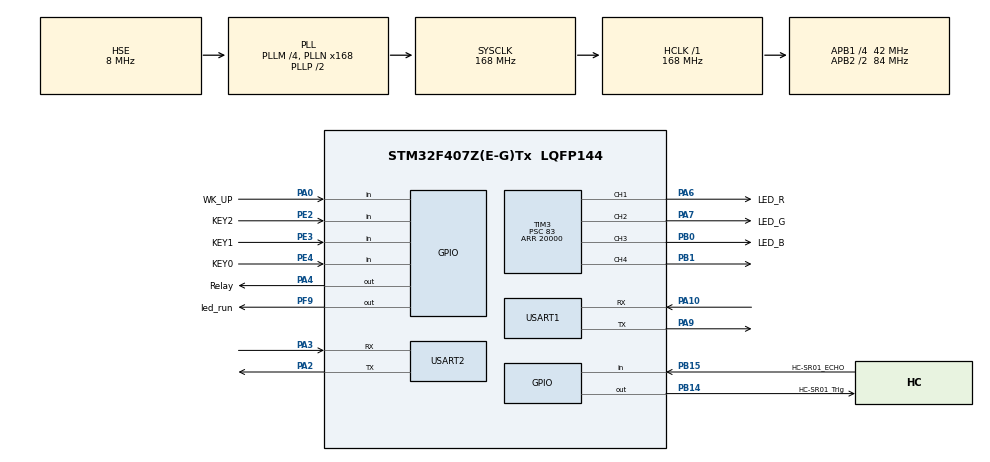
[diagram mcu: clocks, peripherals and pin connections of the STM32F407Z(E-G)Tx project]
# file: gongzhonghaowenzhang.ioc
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Mcu.Family=STM32F4
Mcu.Name=STM32F407Z(E-G)Tx
Mcu.Package=LQFP144
NVIC.PriorityGroup=NVIC_PRIORITYGROUP_4
NVIC.RCC_IRQn=true\:0\:0\:false\:false\:true\:true
NVIC.TIM2_IRQn=true\:0\:0\:false\:false\:true\:true
NVIC.TIM3_IRQn=true\:0\:0\:false\:false\:true\:true
NVIC.TIM7_IRQn=true\:0\:0\:false\:false\:true\:true
NVIC.USART1_IRQn=true\:0\:0\:false\:false\:true\:true
NVIC.USART2_IRQn=true\:0\:0\:false\:false\:true\:true
PA0-WKUP.GPIO_Label=WK_UP
PA0-WKUP.GPIO_PuPd=GPIO_PULLDOWN
PA0-WKUP.Signal=GPIO_Input
PA10.Mode=Asynchronous
PA10.Signal=USART1_RX
PA13.Mode=JTAG_5_pins
PA13.Signal=SYS_JTMS-SWDIO
PA14.Mode=JTAG_5_pins
PA14.Signal=SYS_JTCK-SWCLK
PA15.Mode=JTAG_5_pins
PA15.Signal=SYS_JTDI
PA2.Mode=Asynchronous
PA2.Signal=USART2_TX
PA3.Mode=Asynchronous
PA3.Signal=USART2_RX
PA4.GPIO_Label=Relay
PA4.Signal=GPIO_Output
PA6.GPIO_Label=LED_R
PA6.Signal=S_TIM3_CH1
PA7.GPIO_Label=LED_G
PA7.Signal=S_TIM3_CH2
PA9.Mode=Asynchronous
PA9.Signal=USART1_TX
PB0.GPIO_Label=LED_B
PB0.Signal=S_TIM3_CH3
PB1.Signal=S_TIM3_CH4
PB14.GPIO_Label=HC-SR01_Trig
PB14.GPIO_PuPd=GPIO_PULLDOWN
PB14.GPIO_Speed=GPIO_SPEED_FREQ_HIGH
PB14.PinState=GPIO_PIN_RESET
PB14.Signal=GPIO_Output
PB15.GPIO_Label=HC-SR01_ECHO
PB15.Signal=GPIO_Input
PB3.Mode=JTAG_5_pins
PB3.Signal=SYS_JTDO-SWO
PB4.Mode=JTAG_5_pins
PB4.Signal=SYS_JTRST
PE2.GPIO_Label=KEY2
PE2.GPIO_PuPd=GPIO_PULLUP
PE2.Signal=GPIO_Input
PE3.GPIO_Label=KEY1
PE3.GPIO_PuPd=GPIO_PULLUP
PE3.Signal=GPIO_Input
PE4.GPIO_Label=KEY0
PE4.GPIO_PuPd=GPIO_PULLUP
PE4.Signal=GPIO_Input
PF9.GPIO_Label=led_run
PF9.Signal=GPIO_Output
PH0-OSC_IN.Mode=HSE-External-Oscillator
PH0-OSC_IN.Signal=RCC_OSC_IN
PH1-OSC_OUT.Mode=HSE-External-Oscillator
PH1-OSC_OUT.Signal=RCC_OSC_OUT
ProjectManager.HeapSize=0x200
ProjectManager.StackSize=0x400
ProjectManager.TargetToolchain=MDK-ARM V5
RCC.48MHZClocksFreq_Value=84000000
RCC.AHBFreq_Value=168000000
RCC.APB1CLKDivider=RCC_HCLK_DIV4
RCC.APB1Freq_Value=42000000
RCC.APB1TimFreq_Value=84000000
RCC.APB2CLKDivider=RCC_HCLK_DIV2
RCC.APB2Freq_Value=84000000
RCC.APB2TimFreq_Value=168000000
RCC.CortexFreq_Value=168000000
RCC.HCLKFreq_Value=168000000
RCC.HSE_VALUE=8000000
RCC.HSI_VALUE=16000000
RCC.LSE_VALUE=32768
RCC.PLLM=4
RCC.PLLN=168
RCC.PLLSourceVirtual=RCC_PLLSOURCE_HSE
RCC.SYSCLKFreq_VALUE=168000000
RCC.SYSCLKSource=RCC_SYSCLKSOURCE_PLLCLK
RCC.VCOOutputFreq_Value=336000000
SH.S_TIM3_CH1.0=TIM3_CH1,PWM Generation1 CH1
SH.S_TIM3_CH2.0=TIM3_CH2,PWM Generation2 CH2
SH.S_TIM3_CH3.0=TIM3_CH3,PWM Generation3 CH3
SH.S_TIM3_CH4.0=TIM3_CH4,PWM Generation4 CH4
TIM2.CounterMode=TIM_COUNTERMODE_UP
TIM2.Period=65535
TIM2.Prescaler=84-1
TIM3.Channel-PWM\ Generation1\ CH1=TIM_CHANNEL_1
TIM3.Channel-PWM\ Generation2\ CH2=TIM_CHANNEL_2
TIM3.Channel-PWM\ Generation3\ CH3=TIM_CHANNEL_3
TIM3.Channel-PWM\ Generation4\ CH4=TIM_CHANNEL_4
TIM3.Period=20000
TIM3.Prescaler=83
TIM7.Period=10
TIM7.Prescaler=8399
USART1.VirtualMode=VM_ASYNC
USART2.VirtualMode=VM_ASYNC
VP_TIM2_VS_ClockSourceINT.Mode=Internal
VP_TIM3_VS_ClockSourceINT.Mode=Internal
VP_TIM7_VS_ClockSourceINT.Mode=Enable_Timer
board=custom

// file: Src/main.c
/* USER CODE BEGIN Header */
/**
  ******************************************************************************
  * @file           : main.c
  * @brief          : Main program body
  ******************************************************************************
  ** This notice applies to any and all portions of this file
  * that are not between comment pairs USER CODE BEGIN and
  * USER CODE END. Other portions of this file, whether
  * inserted by the user or by software development tools
  * are owned by their respective copyright owners.
  *
  * COPYRIGHT(c) 2021 STMicroelectronics
  *
  * Redistribution and use in source and binary forms, with or without modification,
  * are permitted provided that the following conditions are met:
  *   1. Redistributions of source code must retain the above copyright notice,
  *      this list of conditions and the following disclaimer.
  *   2. Redistributions in binary form must reproduce the above copyright notice,
  *      this list of conditions and the following disclaimer in the documentation
  *      and/or other materials provided with the distribution.
  *   3. Neither the name of STMicroelectronics nor the names of its contributors
  *      may be used to endorse or promote products derived from this software
  *      without specific prior written permission.
  *
  * THIS SOFTWARE IS PROVIDED BY THE COPYRIGHT HOLDERS AND CONTRIBUTORS "AS IS"
  * AND ANY EXPRESS OR IMPLIED WARRANTIES, INCLUDING, BUT NOT LIMITED TO, THE
  * IMPLIED WARRANTIES OF MERCHANTABILITY AND FITNESS FOR A PARTICULAR PURPOSE ARE
  * DISCLAIMED. IN NO EVENT SHALL THE COPYRIGHT HOLDER OR CONTRIBUTORS BE LIABLE
  * FOR ANY DIRECT, INDIRECT, INCIDENTAL, SPECIAL, EXEMPLARY, OR CONSEQUENTIAL
  * DAMAGES (INCLUDING, BUT NOT LIMITED TO, PROCUREMENT OF SUBSTITUTE GOODS OR
  * SERVICES; LOSS OF USE, DATA, OR PROFITS; OR BUSINESS INTERRUPTION) HOWEVER
  * CAUSED AND ON ANY THEORY OF LIABILITY, WHETHER IN CONTRACT, STRICT LIABILITY,
  * OR TORT (INCLUDING NEGLIGENCE OR OTHERWISE) ARISING IN ANY WAY OUT OF THE USE
  * OF THIS SOFTWARE, EVEN IF ADVISED OF THE POSSIBILITY OF SUCH DAMAGE.
  *
  ******************************************************************************
  */
/* USER CODE END Header */

#include "main.h"
#include "tim.h"
#include "usart.h"
#include "gpio.h"

/* USER CODE BEGIN Includes */
#include "user_key.h"
#include "user_delay.h"
#include "hcsr04.h"
/* USER CODE END Includes */

void SystemClock_Config(void);

int main(void)
{
  /* USER CODE BEGIN 1 */
	uint8_t key = 0,t=0;
	float distant = 0;
  /* USER CODE END 1 */

  /* MCU Configuration--------------------------------------------------------*/

  /* Reset of all peripherals, Initializes the Flash interface and the Systick. */
  HAL_Init();

  /* Configure the system clock */
  SystemClock_Config();

  /* Initialize all configured peripherals */
  MX_GPIO_Init();
  MX_USART2_UART_Init();
  MX_TIM3_Init();
  MX_USART1_UART_Init();
  MX_TIM2_Init();
  MX_TIM7_Init();
  /* USER CODE BEGIN 2 */
  HAL_Delay_us_init(168);
  /* USER CODE END 2 */

  /* Infinite loop */
  while (1)
  {

    /* USER CODE BEGIN 3 */
//		distant =  HCSR04_Get_Time();
//		key=KEY_Scan(0);
//		switch (key)
//		{
//			case WKUP_PRES:			//
//				PWM_Output(1);
//				printf("rotate -90��\r\n");
//				break;
//			case KEY2_PRES:			//
//				PWM_Output(2);
//				printf("rotate -45��\r\n");

//				break;
//			case KEY1_PRES:			//
//				PWM_Output(4);
//				printf("rotate 45��\r\n");
//				break;
//			case KEY0_PRES:			//
//				PWM_Output(5);
//				printf("rotate 90��\r\n");
//				break;
//		}
//		t++;
//		if(t%200==0)
//		{
//			t=0;
//			printf("%f\r\n",distant);
//			printf("test\r\n");
//		}
		HAL_GPIO_TogglePin(led_run_GPIO_Port,led_run_Pin);
		for_delay_us(20);
		//HAL_Delay_us(20);
		//user_delaynus_tim(200);
		//user_delaynus(20);
		//delay_ms(500);
		//HAL_Delay(100);
  }
  /* USER CODE END 3 */
}

void SystemClock_Config(void)
{
  RCC_OscInitTypeDef RCC_OscInitStruct = {0};
  RCC_ClkInitTypeDef RCC_ClkInitStruct = {0};

  /**Configure the main internal regulator output voltage
  */
  __HAL_RCC_PWR_CLK_ENABLE();
  __HAL_PWR_VOLTAGESCALING_CONFIG(PWR_REGULATOR_VOLTAGE_SCALE1);
  /**Initializes the CPU, AHB and APB busses clocks
  */
  RCC_OscInitStruct.OscillatorType = RCC_OSCILLATORTYPE_HSE;
  RCC_OscInitStruct.HSEState = RCC_HSE_ON;
  RCC_OscInitStruct.PLL.PLLState = RCC_PLL_ON;
  RCC_OscInitStruct.PLL.PLLSource = RCC_PLLSOURCE_HSE;
  RCC_OscInitStruct.PLL.PLLM = 4;
  RCC_OscInitStruct.PLL.PLLN = 168;
  RCC_OscInitStruct.PLL.PLLP = RCC_PLLP_DIV2;
  RCC_OscInitStruct.PLL.PLLQ = 4;
  if (HAL_RCC_OscConfig(&RCC_OscInitStruct) != HAL_OK)
  {
    Error_Handler();
  }
  /**Initializes the CPU, AHB and APB busses clocks
  */
  RCC_ClkInitStruct.ClockType = RCC_CLOCKTYPE_HCLK|RCC_CLOCKTYPE_SYSCLK
                              |RCC_CLOCKTYPE_PCLK1|RCC_CLOCKTYPE_PCLK2;
  RCC_ClkInitStruct.SYSCLKSource = RCC_SYSCLKSOURCE_PLLCLK;
  RCC_ClkInitStruct.AHBCLKDivider = RCC_SYSCLK_DIV1;
  RCC_ClkInitStruct.APB1CLKDivider = RCC_HCLK_DIV4;
  RCC_ClkInitStruct.APB2CLKDivider = RCC_HCLK_DIV2;

  if (HAL_RCC_ClockConfig(&RCC_ClkInitStruct, FLASH_LATENCY_5) != HAL_OK)
  {
    Error_Handler();
  }
}

void Error_Handler(void)
{
}

/************************ (C) COPYRIGHT STMicroelectronics *****END OF FILE****/
